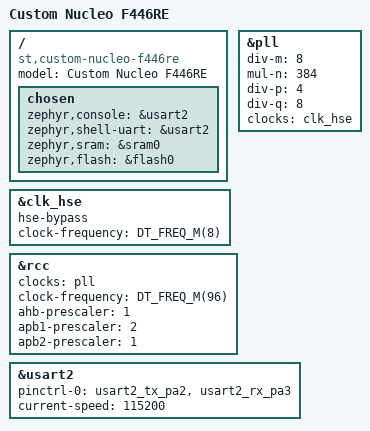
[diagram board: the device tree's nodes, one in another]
/*
 * SPDX-License-Identifier: Apache-2.0
 */

/dts-v1/;

#include <st/f4/stm32f446Xe.dtsi>
#include <st/f4/stm32f446r(c-e)tx-pinctrl.dtsi>

/ {
	model = "Custom Nucleo F446RE";
	compatible = "st,custom-nucleo-f446re";

	chosen {
		zephyr,console = &usart2;
		zephyr,shell-uart = &usart2;
		zephyr,sram = &sram0;
		zephyr,flash = &flash0;
	};
};

&clk_hse {
	hse-bypass;
	clock-frequency = <DT_FREQ_M(8)>;
	status = "okay";
};

&pll {
	div-m = <8>;
	mul-n = <384>;
	div-p = <4>;
	div-q = <8>;
	clocks = <&clk_hse>;
	status = "okay";
};

&rcc {
	clocks = <&pll>;
	clock-frequency = <DT_FREQ_M(96)>;
	ahb-prescaler = <1>;
	apb1-prescaler = <2>;
	apb2-prescaler = <1>;
};

&usart2 {
	pinctrl-0 = <&usart2_tx_pa2 &usart2_rx_pa3>;
	pinctrl-names = "default";
	current-speed = <115200>;
	status = "okay";
};
